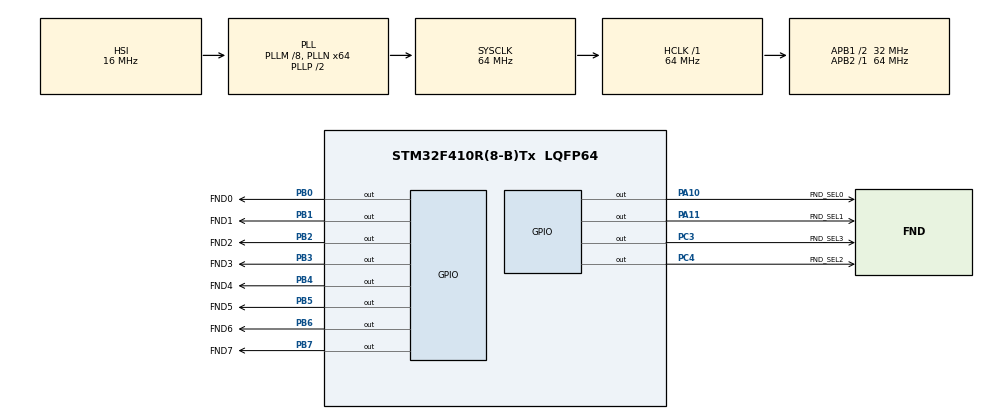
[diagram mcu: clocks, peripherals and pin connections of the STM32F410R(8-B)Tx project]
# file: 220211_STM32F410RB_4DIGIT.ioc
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Mcu.Family=STM32F4
Mcu.Name=STM32F410R(8-B)Tx
Mcu.Package=LQFP64
NVIC.PriorityGroup=NVIC_PRIORITYGROUP_4
PA10.GPIO_Label=FND_SEL0
PA10.Signal=GPIO_Output
PA11.GPIO_Label=FND_SEL1
PA11.Signal=GPIO_Output
PA13.Mode=Serial_Wire
PA13.Signal=SYS_JTMS-SWDIO
PA14.Mode=Serial_Wire
PA14.Signal=SYS_JTCK-SWCLK
PB0.GPIO_Label=FND0
PB0.Signal=GPIO_Output
PB1.GPIO_Label=FND1
PB1.Signal=GPIO_Output
PB2.GPIO_Label=FND2
PB2.Signal=GPIO_Output
PB3.GPIO_Label=FND3
PB3.Signal=GPIO_Output
PB4.GPIO_Label=FND4
PB4.Signal=GPIO_Output
PB5.GPIO_Label=FND5
PB5.Signal=GPIO_Output
PB6.GPIO_Label=FND6
PB6.Signal=GPIO_Output
PB7.GPIO_Label=FND7
PB7.Signal=GPIO_Output
PC14-OSC32_IN.Mode=LSE-External-Oscillator
PC14-OSC32_IN.Signal=RCC_OSC32_IN
PC15-OSC32_OUT.Mode=LSE-External-Oscillator
PC15-OSC32_OUT.Signal=RCC_OSC32_OUT
PC3.GPIO_Label=FND_SEL3
PC3.Signal=GPIO_Output
PC4.GPIO_Label=FND_SEL2
PC4.Signal=GPIO_Output
ProjectManager.HeapSize=0x200
ProjectManager.StackSize=0x400
ProjectManager.TargetToolchain=STM32CubeIDE
RCC.48MHZClocksFreq_Value=32000000
RCC.AHBFreq_Value=64000000
RCC.APB1CLKDivider=RCC_HCLK_DIV2
RCC.APB1Freq_Value=32000000
RCC.APB1TimFreq_Value=64000000
RCC.APB2Freq_Value=64000000
RCC.APB2TimFreq_Value=64000000
RCC.CortexFreq_Value=64000000
RCC.HCLKFreq_Value=64000000
RCC.HSE_VALUE=25000000
RCC.HSI_VALUE=16000000
RCC.PLLM=8
RCC.PLLN=64
RCC.SYSCLKFreq_VALUE=64000000
RCC.SYSCLKSource=RCC_SYSCLKSOURCE_PLLCLK
RCC.VCOOutputFreq_Value=128000000
board=custom

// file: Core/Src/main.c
/* USER CODE BEGIN Header */
/**
  ******************************************************************************
  * @file           : main.c
  * @brief          : Main program body
  ******************************************************************************
  * @attention
  *
  * Copyright (c) 2022 STMicroelectronics.
  * All rights reserved.
  *
  * This software is licensed under terms that can be found in the LICENSE file
  * in the root directory of this software component.
  * If no LICENSE file comes with this software, it is provided AS-IS.
  *
  ******************************************************************************
  */
/* USER CODE END Header */
#include "main.h"

/* USER CODE BEGIN Includes */
#include "7segment.h"

/* USER CODE END Includes */

void SystemClock_Config(void);
static void MX_GPIO_Init(void);

int main(void)
{

  /* MCU Configuration--------------------------------------------------------*/

  /* Reset of all peripherals, Initializes the Flash interface and the Systick. */
  HAL_Init();

  /* Configure the system clock */
  SystemClock_Config();

  /* Initialize all configured peripherals */
  MX_GPIO_Init();
  /* USER CODE BEGIN 2 */

  SevenSeg_GPIO_Init();

  /* USER CODE END 2 */

  /* Infinite loop */
  while (1)
  {

    /* USER CODE BEGIN 3 */
//	  HAL_GPIO_WritePin(GPIOB, FND0_Pin|FND1_Pin|FND2_Pin|FND3_Pin|FND4_Pin|FND5_Pin|FND6_Pin|FND7_Pin, GPIO_PIN_SET);
	  SevenSeg_SetNumber(DIGIT_1ST, 2, ON);
  }
  /* USER CODE END 3 */
}

void SystemClock_Config(void)
{
  RCC_OscInitTypeDef RCC_OscInitStruct = {0};
  RCC_ClkInitTypeDef RCC_ClkInitStruct = {0};

  /** Configure the main internal regulator output voltage
  */
  __HAL_RCC_PWR_CLK_ENABLE();
  __HAL_PWR_VOLTAGESCALING_CONFIG(PWR_REGULATOR_VOLTAGE_SCALE1);
  /** Initializes the RCC Oscillators according to the specified parameters
  * in the RCC_OscInitTypeDef structure.
  */
  RCC_OscInitStruct.OscillatorType = RCC_OSCILLATORTYPE_HSI;
  RCC_OscInitStruct.HSIState = RCC_HSI_ON;
  RCC_OscInitStruct.HSICalibrationValue = RCC_HSICALIBRATION_DEFAULT;
  RCC_OscInitStruct.PLL.PLLState = RCC_PLL_ON;
  RCC_OscInitStruct.PLL.PLLSource = RCC_PLLSOURCE_HSI;
  RCC_OscInitStruct.PLL.PLLM = 8;
  RCC_OscInitStruct.PLL.PLLN = 64;
  RCC_OscInitStruct.PLL.PLLP = RCC_PLLP_DIV2;
  RCC_OscInitStruct.PLL.PLLQ = 4;
  RCC_OscInitStruct.PLL.PLLR = 2;
  if (HAL_RCC_OscConfig(&RCC_OscInitStruct) != HAL_OK)
  {
    Error_Handler();
  }
  /** Initializes the CPU, AHB and APB buses clocks
  */
  RCC_ClkInitStruct.ClockType = RCC_CLOCKTYPE_HCLK|RCC_CLOCKTYPE_SYSCLK
                              |RCC_CLOCKTYPE_PCLK1|RCC_CLOCKTYPE_PCLK2;
  RCC_ClkInitStruct.SYSCLKSource = RCC_SYSCLKSOURCE_PLLCLK;
  RCC_ClkInitStruct.AHBCLKDivider = RCC_SYSCLK_DIV1;
  RCC_ClkInitStruct.APB1CLKDivider = RCC_HCLK_DIV2;
  RCC_ClkInitStruct.APB2CLKDivider = RCC_HCLK_DIV1;

  if (HAL_RCC_ClockConfig(&RCC_ClkInitStruct, FLASH_LATENCY_1) != HAL_OK)
  {
    Error_Handler();
  }
}

static void MX_GPIO_Init(void)
{
  GPIO_InitTypeDef GPIO_InitStruct = {0};

  /* GPIO Ports Clock Enable */
  __HAL_RCC_GPIOC_CLK_ENABLE();
  __HAL_RCC_GPIOB_CLK_ENABLE();
  __HAL_RCC_GPIOA_CLK_ENABLE();

  /*Configure GPIO pin Output Level */
  HAL_GPIO_WritePin(GPIOC, FND_SEL3_Pin|FND_SEL2_Pin, GPIO_PIN_RESET);

  /*Configure GPIO pin Output Level */
  HAL_GPIO_WritePin(GPIOB, FND0_Pin|FND1_Pin|FND2_Pin|FND3_Pin
                          |FND4_Pin|FND5_Pin|FND6_Pin|FND7_Pin, GPIO_PIN_RESET);

  /*Configure GPIO pin Output Level */
  HAL_GPIO_WritePin(GPIOA, FND_SEL0_Pin|FND_SEL1_Pin, GPIO_PIN_RESET);

  /*Configure GPIO pins : FND_SEL3_Pin FND_SEL2_Pin */
  GPIO_InitStruct.Pin = FND_SEL3_Pin|FND_SEL2_Pin;
  GPIO_InitStruct.Mode = GPIO_MODE_OUTPUT_PP;
  GPIO_InitStruct.Pull = GPIO_NOPULL;
  GPIO_InitStruct.Speed = GPIO_SPEED_FREQ_LOW;
  HAL_GPIO_Init(GPIOC, &GPIO_InitStruct);

  /*Configure GPIO pins : FND0_Pin FND1_Pin FND2_Pin FND3_Pin
                           FND4_Pin FND5_Pin FND6_Pin FND7_Pin */
  GPIO_InitStruct.Pin = FND0_Pin|FND1_Pin|FND2_Pin|FND3_Pin
                          |FND4_Pin|FND5_Pin|FND6_Pin|FND7_Pin;
  GPIO_InitStruct.Mode = GPIO_MODE_OUTPUT_PP;
  GPIO_InitStruct.Pull = GPIO_NOPULL;
  GPIO_InitStruct.Speed = GPIO_SPEED_FREQ_LOW;
  HAL_GPIO_Init(GPIOB, &GPIO_InitStruct);

  /*Configure GPIO pins : FND_SEL0_Pin FND_SEL1_Pin */
  GPIO_InitStruct.Pin = FND_SEL0_Pin|FND_SEL1_Pin;
  GPIO_InitStruct.Mode = GPIO_MODE_OUTPUT_PP;
  GPIO_InitStruct.Pull = GPIO_NOPULL;
  GPIO_InitStruct.Speed = GPIO_SPEED_FREQ_LOW;
  HAL_GPIO_Init(GPIOA, &GPIO_InitStruct);

}

void Error_Handler(void)
{
  __disable_irq();
  while (1)
  {
  }
}
